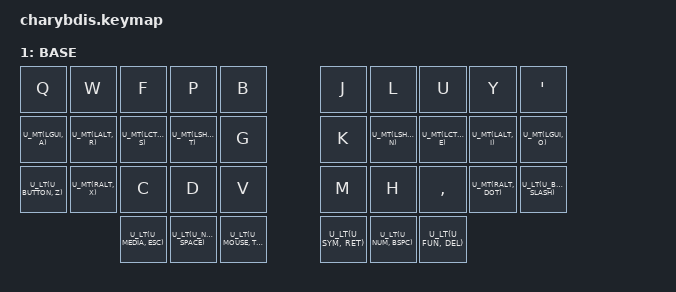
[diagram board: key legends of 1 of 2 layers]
#include "keys_nb_osx.h"
#include "keys_nb_win.h"
#include <behaviors.dtsi>
#include "behaviours.dtsi"
#include "behaviours.h"
#include <dt-bindings/zmk/bt.h>
#include <dt-bindings/zmk/keys.h>
#include <dt-bindings/zmk/pointing.h>
#include "combos.dtsi"

&caps_word { 
    continue-list = <NB_UNDERSCORE NB_MINUS WNB_UNDERSCORE WNB_MINUS BACKSPACE DEL>; 
    };

// Change sticky key defaults

&sk {
    release-after-ms = <2000>;
    quick-release;
};

&lt { quick-tap-ms = <175>; };

/ {
    chosen { zmk,matrix_transform = &five_column_transform; };
};

/ {
    behaviors {
    };
    
    keymap {
        compatible = "zmk,keymap";

        default {
            bindings = <       
                &kp Q           &kp W           &kp F           &kp P       &kp B           &kp J           &kp L       &kp U       &kp Y       &kp SQT
                &kp A           &kp R           &kp S           &kp T       &kp G           &kp M           &kp N       &kp E       &kp I       &kp O
                &kp Z           &kp X           &kp C           &kp D       &kp V           &kp K           &hkp H      &kp COMMA   &kp DOT     &kp SLASH
                                                &kp ESC         &kp SPACE   &kp TAB         &kp RET         &kp BSPC
            >;

            display-name = "DEFAULT";
            label = "DEFAULT";
        };

        base {
            bindings = <
                &kp Q             &kp W             &kp F              &kp P               &kp B              &kp J              &kp L              &kp U              &kp Y              &kp SQT
                U_MT(LGUI, A)     U_MT(LALT, R)     U_MT(LCTRL, S)     U_MT(LSHFT, T)      &kp G              &kp K              U_MT(LSHFT, N)     U_MT(LCTRL, E)     U_MT(LALT, I)      U_MT(LGUI, O)
                U_LT(U_BUTTON, Z) U_MT(RALT, X)     &kp C              &kp D               &kp V              &kp M              &kp H              &kp COMMA          U_MT(RALT, DOT)    U_LT(U_BUTTON, SLASH)
                                                    U_LT(U_MEDIA, ESC) U_LT(U_NAV, SPACE)  U_LT(U_MOUSE, TAB) U_LT(U_SYM, RET)   U_LT(U_NUM, BSPC)  U_LT(U_FUN, DEL)   
            >;

            display-name = "BASE";
            label = "BASE";
        };
    };
};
